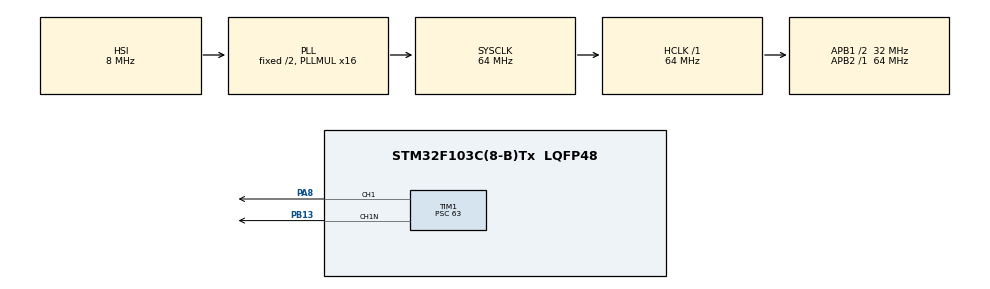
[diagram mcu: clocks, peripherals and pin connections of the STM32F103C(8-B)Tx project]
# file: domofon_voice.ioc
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Mcu.Family=STM32F1
Mcu.Name=STM32F103C(8-B)Tx
Mcu.Package=LQFP48
NVIC.PriorityGroup=NVIC_PRIORITYGROUP_4
NVIC.TIM1_BRK_IRQn=true\:0\:0\:false\:false\:true\:true\:true\:true
NVIC.TIM1_CC_IRQn=true\:0\:0\:false\:false\:true\:true\:true\:true
NVIC.TIM1_TRG_COM_IRQn=true\:0\:0\:false\:false\:true\:true\:true\:true
NVIC.TIM1_UP_IRQn=true\:0\:0\:false\:false\:true\:true\:true\:true
NVIC.TIM2_IRQn=true\:0\:0\:false\:false\:true\:true\:true\:true
PA13.Mode=Serial_Wire
PA13.Signal=SYS_JTMS-SWDIO
PA14.Mode=Serial_Wire
PA14.Signal=SYS_JTCK-SWCLK
PA8.Signal=S_TIM1_CH1
PB13.Mode=PWM Generation1 CH1 CH1N
PB13.Signal=TIM1_CH1N
ProjectManager.HeapSize=0x200
ProjectManager.StackSize=0x400
ProjectManager.TargetToolchain=STM32CubeIDE
RCC.AHBFreq_Value=64000000
RCC.APB1CLKDivider=RCC_HCLK_DIV2
RCC.APB1Freq_Value=32000000
RCC.APB1TimFreq_Value=64000000
RCC.APB2Freq_Value=64000000
RCC.APB2TimFreq_Value=64000000
RCC.HCLKFreq_Value=64000000
RCC.PLLMUL=RCC_PLL_MUL16
RCC.SYSCLKFreq_VALUE=64000000
RCC.SYSCLKSource=RCC_SYSCLKSOURCE_PLLCLK
RCC.USBFreq_Value=64000000
SH.S_TIM1_CH1.0=TIM1_CH1,PWM Generation1 CH1 CH1N
TIM1.AutoReloadPreload=TIM_AUTORELOAD_PRELOAD_ENABLE
TIM1.Channel-PWM\ Generation1\ CH1\ CH1N=TIM_CHANNEL_1
TIM1.OCPolarity_1=TIM_OCPOLARITY_LOW
TIM1.Period=183
TIM1.Prescaler=63
TIM1.Pulse-PWM\ Generation1\ CH1\ CH1N=160
TIM2.AutoReloadPreload=TIM_AUTORELOAD_PRELOAD_ENABLE
TIM2.Period=7999
VP_TIM1_VS_ClockSourceINT.Mode=Internal
VP_TIM2_VS_ClockSourceINT.Mode=Internal
board=custom

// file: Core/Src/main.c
/* USER CODE BEGIN Header */
/**
  ******************************************************************************
  * @file           : main.c
  * @brief          : Main program body
  ******************************************************************************
  * @attention
  *
  * Copyright (c) 2025 STMicroelectronics.
  * All rights reserved.
  *
  * This software is licensed under terms that can be found in the LICENSE file
  * in the root directory of this software component.
  * If no LICENSE file comes with this software, it is provided AS-IS.
  *
  ******************************************************************************
  */
/* USER CODE END Header */
#include "main.h"

/* USER CODE BEGIN Includes */
#include "levitan.h"
/* USER CODE END Includes */

TIM_HandleTypeDef htim1;
TIM_HandleTypeDef htim2;

void SystemClock_Config(void);
static void MX_GPIO_Init(void);
static void MX_TIM1_Init(void);
static void MX_TIM2_Init(void);
/* USER CODE BEGIN PFP */

uint16_t cnt_music = 0;
uint8_t music = 0;
uint32_t cnt_pwm = 0;

void HAL_TIM_PWM_PulseFinishedCallback(TIM_HandleTypeDef *htim)
{
    if(htim->Instance == TIM1) //check if the interrupt comes from TIM1
    {
    	cnt_pwm++;
    	if(cnt_pwm == 15)
    	{
    		TIM1->CCR1 = 183;

    		//HAL_TIM_PWM_Stop_IT(&htim1, TIM_CHANNEL_1);
    	}

    }
}

void HAL_TIM_PeriodElapsedCallback(TIM_HandleTypeDef *htim)
{
        if(htim->Instance == TIM2) //check if the interrupt comes from TIM1
        {
    		TIM1->CCR1 = lev_8bit[cnt_music];
    		if(cnt_music == 8925)
    		{
    			cnt_music = 0;
    		}
    		cnt_music++;
        }
}

uint32_t call_mass[255];

void init_call_mass()
{
	for(int i = 0; i < 250; i++)
	{
		call_mass[i] = 20;
	}
}
void call(int num)
{

	HAL_TIM_PWM_Stop(&htim1, TIM_CHANNEL_1);
	TIM1->CNT = 0;
	TIM1->CCR1 = 140;
	HAL_TIM_PWM_Start_IT(&htim1, TIM_CHANNEL_1);

	  ///HAL_TIM_PWM_Start_DMA(&htim1, TIM_CHANNEL_2, call_mass, num);
}

void old_programm()
{
	  ///TIM1->CCR1 = 183;
	  //HAL_TIM_PWM_Start(&htim1, TIM_CHANNEL_1);
	  GPIOA->CRH &=~(0x02<<GPIO_CRH_CNF8_Pos);
	  GPIOA->ODR &= ~(1<<8);
	  HAL_Delay(260);//HAL_Delay(4260);
	  ///TIM1->CCR1 = 0;
	  GPIOA->ODR |= (1<<8);
	  HAL_Delay(260);
	  GPIOA->ODR &= ~(1<<8);
	  GPIOA->CRH |=(0x02<<GPIO_CRH_CNF8_Pos);
	  //TIM1->CCR1 = 183;
	  ///HAL_TIM_PWM_Stop(&htim1, TIM_CHANNEL_1);
	  MX_GPIO_Init();
	  MX_TIM1_Init();

	  HAL_Delay(260);
	  ///HAL_TIM_PWM_Stop(&htim1, TIM_CHANNEL_1);
	  call(255);

	  HAL_Delay(1000);
	  ///TIM1->CCR1 = 150;
	  TIM1->ARR = 256;
	  TIM1->PSC = 16;
	  HAL_TIM_PWM_Stop_IT(&htim1, TIM_CHANNEL_1);
	  HAL_TIM_PWM_Start(&htim1, TIM_CHANNEL_1);
	  HAL_TIM_Base_Start_IT(&htim2);
	  //HAL_TIM_PWM_Start_IT(&htim1, TIM_CHANNEL_1);
}
/* USER CODE END PFP */

int main(void)
{

  /* MCU Configuration--------------------------------------------------------*/

  /* Reset of all peripherals, Initializes the Flash interface and the Systick. */
  HAL_Init();

  /* Configure the system clock */
  SystemClock_Config();

  /* Initialize all configured peripherals */
  MX_GPIO_Init();
  MX_TIM1_Init();
  MX_TIM2_Init();
  /* USER CODE BEGIN 2 */

  old_programm();
  while(1);

  TIM1->CCR1 = 183;
  HAL_TIM_PWM_Start(&htim1, TIM_CHANNEL_1);
  HAL_TIMEx_PWMN_Start(&htim1, TIM_CHANNEL_1);

  HAL_Delay(3260);
  TIM1->CCR1 = 0;

  HAL_Delay(267);

  TIM1->CCR1 = 183;
  //HAL_TIM_PWM_Stop(&htim1, TIM_CHANNEL_1);

  HAL_Delay(100);
  call(255);

  while(cnt_pwm != 255);

  HAL_Delay(8);
  ///TIM1->CCR1 = 0;
  HAL_Delay(300);
  ///TIM1->CCR1 = 150;
  TIM1->ARR = 256;
  TIM1->PSC = 16;
  TIM1->CNT = 0;
  TIM1->CCR1 = 0;
  //HAL_TIM_PWM_Stop_IT(&htim1, TIM_CHANNEL_1);
  //HAL_TIMEx_PWMN_Stop_IT(&htim1, TIM_CHANNEL_1);

  HAL_TIM_PWM_Start(&htim1, TIM_CHANNEL_1);
  HAL_TIMEx_PWMN_Start(&htim1, TIM_CHANNEL_1);

  HAL_TIM_Base_Start_IT(&htim2);
  //HAL_TIM_PWM_Start_IT(&htim1, TIM_CHANNEL_1);
  /* USER CODE END 2 */

  /* Infinite loop */
  while (1)
  {

  }
}

void SystemClock_Config(void)
{
  RCC_OscInitTypeDef RCC_OscInitStruct = {0};
  RCC_ClkInitTypeDef RCC_ClkInitStruct = {0};

  /** Initializes the RCC Oscillators according to the specified parameters
  * in the RCC_OscInitTypeDef structure.
  */
  RCC_OscInitStruct.OscillatorType = RCC_OSCILLATORTYPE_HSI;
  RCC_OscInitStruct.HSIState = RCC_HSI_ON;
  RCC_OscInitStruct.HSICalibrationValue = RCC_HSICALIBRATION_DEFAULT;
  RCC_OscInitStruct.PLL.PLLState = RCC_PLL_ON;
  RCC_OscInitStruct.PLL.PLLSource = RCC_PLLSOURCE_HSI_DIV2;
  RCC_OscInitStruct.PLL.PLLMUL = RCC_PLL_MUL16;
  if (HAL_RCC_OscConfig(&RCC_OscInitStruct) != HAL_OK)
  {
    Error_Handler();
  }

  /** Initializes the CPU, AHB and APB buses clocks
  */
  RCC_ClkInitStruct.ClockType = RCC_CLOCKTYPE_HCLK|RCC_CLOCKTYPE_SYSCLK
                              |RCC_CLOCKTYPE_PCLK1|RCC_CLOCKTYPE_PCLK2;
  RCC_ClkInitStruct.SYSCLKSource = RCC_SYSCLKSOURCE_PLLCLK;
  RCC_ClkInitStruct.AHBCLKDivider = RCC_SYSCLK_DIV1;
  RCC_ClkInitStruct.APB1CLKDivider = RCC_HCLK_DIV2;
  RCC_ClkInitStruct.APB2CLKDivider = RCC_HCLK_DIV1;

  if (HAL_RCC_ClockConfig(&RCC_ClkInitStruct, FLASH_LATENCY_2) != HAL_OK)
  {
    Error_Handler();
  }
}

static void MX_TIM1_Init(void)
{

  TIM_ClockConfigTypeDef sClockSourceConfig = {0};
  TIM_MasterConfigTypeDef sMasterConfig = {0};
  TIM_OC_InitTypeDef sConfigOC = {0};
  TIM_BreakDeadTimeConfigTypeDef sBreakDeadTimeConfig = {0};

  htim1.Instance = TIM1;
  htim1.Init.Prescaler = 63;
  htim1.Init.CounterMode = TIM_COUNTERMODE_UP;
  htim1.Init.Period = 183;
  htim1.Init.ClockDivision = TIM_CLOCKDIVISION_DIV1;
  htim1.Init.RepetitionCounter = 0;
  htim1.Init.AutoReloadPreload = TIM_AUTORELOAD_PRELOAD_ENABLE;
  if (HAL_TIM_Base_Init(&htim1) != HAL_OK)
  {
    Error_Handler();
  }
  sClockSourceConfig.ClockSource = TIM_CLOCKSOURCE_INTERNAL;
  if (HAL_TIM_ConfigClockSource(&htim1, &sClockSourceConfig) != HAL_OK)
  {
    Error_Handler();
  }
  if (HAL_TIM_PWM_Init(&htim1) != HAL_OK)
  {
    Error_Handler();
  }
  sMasterConfig.MasterOutputTrigger = TIM_TRGO_RESET;
  sMasterConfig.MasterSlaveMode = TIM_MASTERSLAVEMODE_DISABLE;
  if (HAL_TIMEx_MasterConfigSynchronization(&htim1, &sMasterConfig) != HAL_OK)
  {
    Error_Handler();
  }
  sConfigOC.OCMode = TIM_OCMODE_PWM1;
  sConfigOC.Pulse = 160;
  sConfigOC.OCPolarity = TIM_OCPOLARITY_LOW;
  sConfigOC.OCNPolarity = TIM_OCNPOLARITY_HIGH;
  sConfigOC.OCFastMode = TIM_OCFAST_DISABLE;
  sConfigOC.OCIdleState = TIM_OCIDLESTATE_RESET;
  sConfigOC.OCNIdleState = TIM_OCNIDLESTATE_RESET;
  if (HAL_TIM_PWM_ConfigChannel(&htim1, &sConfigOC, TIM_CHANNEL_1) != HAL_OK)
  {
    Error_Handler();
  }
  sBreakDeadTimeConfig.OffStateRunMode = TIM_OSSR_DISABLE;
  sBreakDeadTimeConfig.OffStateIDLEMode = TIM_OSSI_DISABLE;
  sBreakDeadTimeConfig.LockLevel = TIM_LOCKLEVEL_OFF;
  sBreakDeadTimeConfig.DeadTime = 0;
  sBreakDeadTimeConfig.BreakState = TIM_BREAK_DISABLE;
  sBreakDeadTimeConfig.BreakPolarity = TIM_BREAKPOLARITY_HIGH;
  sBreakDeadTimeConfig.AutomaticOutput = TIM_AUTOMATICOUTPUT_DISABLE;
  if (HAL_TIMEx_ConfigBreakDeadTime(&htim1, &sBreakDeadTimeConfig) != HAL_OK)
  {
    Error_Handler();
  }
  HAL_TIM_MspPostInit(&htim1);

}

static void MX_TIM2_Init(void)
{

  TIM_ClockConfigTypeDef sClockSourceConfig = {0};
  TIM_MasterConfigTypeDef sMasterConfig = {0};

  htim2.Instance = TIM2;
  htim2.Init.Prescaler = 0;
  htim2.Init.CounterMode = TIM_COUNTERMODE_UP;
  htim2.Init.Period = 7999;
  htim2.Init.ClockDivision = TIM_CLOCKDIVISION_DIV1;
  htim2.Init.AutoReloadPreload = TIM_AUTORELOAD_PRELOAD_ENABLE;
  if (HAL_TIM_Base_Init(&htim2) != HAL_OK)
  {
    Error_Handler();
  }
  sClockSourceConfig.ClockSource = TIM_CLOCKSOURCE_INTERNAL;
  if (HAL_TIM_ConfigClockSource(&htim2, &sClockSourceConfig) != HAL_OK)
  {
    Error_Handler();
  }
  sMasterConfig.MasterOutputTrigger = TIM_TRGO_RESET;
  sMasterConfig.MasterSlaveMode = TIM_MASTERSLAVEMODE_DISABLE;
  if (HAL_TIMEx_MasterConfigSynchronization(&htim2, &sMasterConfig) != HAL_OK)
  {
    Error_Handler();
  }

}

static void MX_GPIO_Init(void)
{

  /* GPIO Ports Clock Enable */
  __HAL_RCC_GPIOB_CLK_ENABLE();
  __HAL_RCC_GPIOA_CLK_ENABLE();

}

void Error_Handler(void)
{
  __disable_irq();
  while (1)
  {
  }
}
